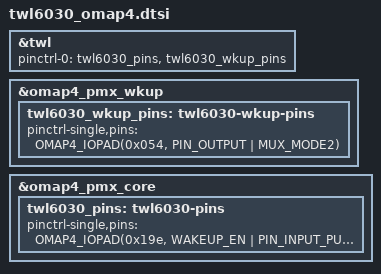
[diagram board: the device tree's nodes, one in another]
&twl {
	pinctrl-names = "default";
	pinctrl-0 = <
		&twl6030_pins
		&twl6030_wkup_pins
	>;
};
&omap4_pmx_wkup {
	twl6030_wkup_pins: twl6030-wkup-pins {
		pinctrl-single,pins = <
			OMAP4_IOPAD(0x054, PIN_OUTPUT | MUX_MODE2)		 
		>;
	};
};
&omap4_pmx_core {
	twl6030_pins: twl6030-pins {
		pinctrl-single,pins = <
			OMAP4_IOPAD(0x19e, WAKEUP_EN | PIN_INPUT_PULLUP | MUX_MODE0)	 
		>;
	};
};
